# MK70F12 register map
Vendor: Freescale Semiconductor, Inc.; Series: Kinetis_K; File version: 1.6
CPU: CM4 r0p1, little endian, no MPU, FPU, VTOR, 4 interrupt priority bits
Registers are 32-bit, read-write, reset 0x0 unless marked. A register's access mark holds for its fields unless they carry their own. Offsets are from the block's base; [hi:lo] are bit positions.

## I2C0 — Inter-Integrated Circuit
Base 0x40066000; register names take the prefix I2C0_
0x00 A1 8-bit — I2C Address Register 1
  [7:1] AD — Address
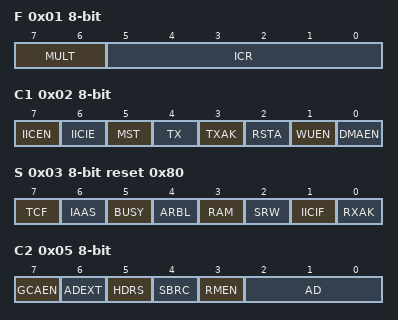
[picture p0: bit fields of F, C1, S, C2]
0x01 F 8-bit — I2C Frequency Divider register
  [7:6] MULT — The MULT bits define the multiplier factor mul
    0=mul = 1; 1=mul = 2; 2=mul = 4
  [5:0] ICR — Clock rate
0x02 C1 8-bit — I2C Control Register 1
  [7] IICEN — I2C enable
    0=Disabled; 1=Enabled
  [6] IICIE — I2C interrupt enable
    0=Disabled; 1=Enabled
  [5] MST — Master mode select
    0=Slave mode; 1=Master mode
  [4] TX — Transmit mode select
    0=Receive; 1=Transmit
  [3] TXAK — Transmit acknowledge enable
    0=An acknowledge signal is sent to the bus on the following (if FACK is cleared) or current (if FACK is set) receiving byte; 1=No acknowledge signal is sent to the bus on the following (if FACK is cleared) or current (if FACK is set) receiving data byte.SCL is held low until TXAK is written
  [2] RSTA wo — Repeat START
  [1] WUEN — Wakeup enable
    0=Normal operation. No interrupt generated when address matching in low power mode.; 1=Enables the wakeup function in low power mode
  [0] DMAEN — DMA enable
    0=All DMA signalling disabled; 1=DMA transfer is enabled and the following conditions trigger the DMA request: While FACK = 0, a data byte is received, either address or data is transmitted. (ACK/NACK automatic) While FACK = 0, the first byte received matches the A1 register or is general call address. If any address matching occurs, IAAS and TCF are set. If the direction of transfer is known from master to slave, then it is not required to check the SRW. With this assumption, DMA can also be used in this case. In other cases, if the master reads data from the slave, then it is required to rewrite the C1 register operation. With this assumption, DMA cannot be used. When FACK = 1, an address or a data byte is transmitted.
0x03 S 8-bit reset 0x80 — I2C Status Register
  [7] TCF ro — Transfer complete flag
    0=Transfer in progress; 1=Transfer complete
  [6] IAAS — Addressed as a slave
    0=Not addressed; 1=Addressed as a slave
  [5] BUSY ro — Bus busy
    0=Bus is idle; 1=Bus is busy
  [4] ARBL — Arbitration lost
    0=Standard bus operation; 1=Loss of arbitration
  [3] RAM — Range address match
    0=Not addressed; 1=Addressed as a slave
  [2] SRW ro — Slave read/write
    0=Slave receive, master writing to slave; 1=Slave transmit, master reading from slave
  [1] IICIF — Interrupt flag
    0=No interrupt pending; 1=Interrupt pending
  [0] RXAK ro — Receive acknowledge
    0=Acknowledge signal was received after the completion of one byte of data transmission on the bus; 1=No acknowledge signal detected
0x04 D 8-bit — I2C Data I/O register
  [7:0] DATA
0x05 C2 8-bit — I2C Control Register 2
  [7] GCAEN — General call address enable
    0=Disabled; 1=Enabled
  [6] ADEXT — Address extension
    0=7-bit address scheme; 1=10-bit address scheme
  [5] HDRS — High drive select
    0=Normal drive mode; 1=High drive mode
  [4] SBRC — Slave baud rate control
    0=The slave baud rate follows the master baud rate and clock stretching may occur; 1=Slave baud rate is independent of the master baud rate
  [3] RMEN — Range address matching enable
    0=Range mode disabled. No address match occurs for an address within the range of values of the A1 and RA registers.; 1=Range mode enabled. Address matching occurs when a slave receives an address within the range of values of the A1 and RA registers.
  [2:0] AD — Slave address
0x06 FLT 8-bit — I2C Programmable Input Glitch Filter register
  [4:0] FLT — I2C programmable filter factor
    0=No filter/bypass
0x07 RA 8-bit — I2C Range Address register
  [7:1] RAD — Range slave address
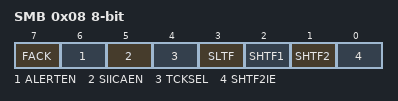
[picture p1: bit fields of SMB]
0x08 SMB 8-bit — I2C SMBus Control and Status register
  [7] FACK — Fast NACK/ACK enable
    0=An ACK or NACK is sent on the following receiving data byte; 1=Writing 0 to TXAK after receiving a data byte generates an ACK. Writing 1 to TXAK after receiving a data byte generates a NACK.
  [6] ALERTEN — SMBus alert response address enable
    0=SMBus alert response address matching is disabled; 1=SMBus alert response address matching is enabled
  [5] SIICAEN — Second I2C address enable
    0=I2C address register 2 matching is disabled; 1=I2C address register 2 matching is enabled
  [4] TCKSEL — Timeout counter clock select
    0=Timeout counter counts at the frequency of the bus clock / 64; 1=Timeout counter counts at the frequency of the bus clock
  [3] SLTF — SCL low timeout flag
    0=No low timeout occurs; 1=Low timeout occurs
  [2] SHTF1 ro — SCL high timeout flag 1
    0=No SCL high and SDA high timeout occurs; 1=SCL high and SDA high timeout occurs
  [1] SHTF2 — SCL high timeout flag 2
    0=No SCL high and SDA low timeout occurs; 1=SCL high and SDA low timeout occurs
  [0] SHTF2IE — SHTF2 interrupt enable
    0=SHTF2 interrupt is disabled; 1=SHTF2 interrupt is enabled
0x09 A2 8-bit reset 0xC2 — I2C Address Register 2
  [7:1] SAD — SMBus address
0x0A SLTH 8-bit — I2C SCL Low Timeout Register High
  [7:0] SSLT — Most significant byte of SCL low timeout value that determines the timeout period of SCL low.
0x0B SLTL 8-bit — I2C SCL Low Timeout Register Low
  [7:0] SSLT — Least significant byte of SCL low timeout value that determines the timeout period of SCL low.

## I2C1 — Inter-Integrated Circuit
Base 0x40067000; register names take the prefix I2C1_
Registers as I2C0.
